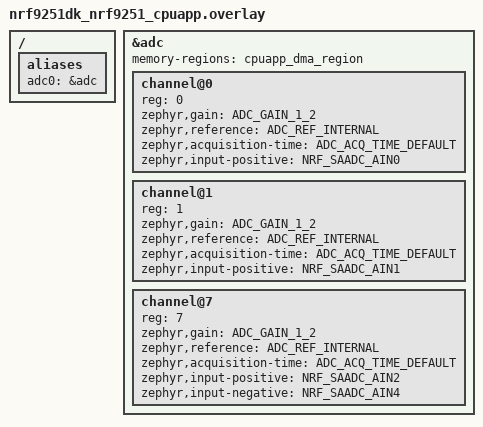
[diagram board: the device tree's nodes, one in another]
/*
 * Copyright (c) 2026 Nordic Semiconductor ASA
 *
 * SPDX-License-Identifier: LicenseRef-Nordic-5-Clause
 */

/ {
	aliases {
		adc0 = &adc;
	};
};

&adc {
	#address-cells = <1>;
	#size-cells = <0>;
	memory-regions = <&cpuapp_dma_region>;
	status = "okay";

	channel@0 {
		reg = <0>;
		zephyr,gain = "ADC_GAIN_1_2";
		zephyr,reference = "ADC_REF_INTERNAL";
		zephyr,acquisition-time = <ADC_ACQ_TIME_DEFAULT>;
		zephyr,input-positive = <NRF_SAADC_AIN0>; /* P1.00 */
	};

	channel@1 {
		reg = <1>;
		zephyr,gain = "ADC_GAIN_1_2";
		zephyr,reference = "ADC_REF_INTERNAL";
		zephyr,acquisition-time = <ADC_ACQ_TIME_DEFAULT>;
		zephyr,input-positive = <NRF_SAADC_AIN1>; /* P1.01 */
	};

	channel@7 {
		reg = <7>;
		zephyr,gain = "ADC_GAIN_1_2";
		zephyr,reference = "ADC_REF_INTERNAL";
		zephyr,acquisition-time = <ADC_ACQ_TIME_DEFAULT>;
		zephyr,input-positive = <NRF_SAADC_AIN2>; /* P1.02 */
		zephyr,input-negative = <NRF_SAADC_AIN4>; /* P1.04 */
	};
};
